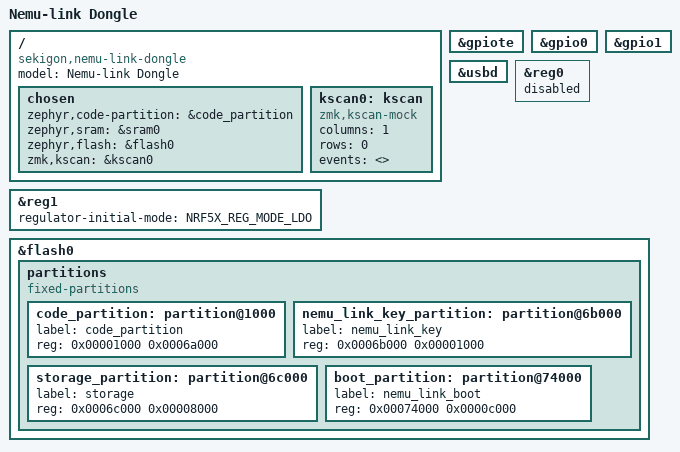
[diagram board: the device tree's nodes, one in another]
/*
 * Copyright (c) 2026 sekigon-gonnoc
 *
 * USB receiver using the nRF52833 clock and UF2 flash layout.
 * This module is intended exclusively for Nemu Link dongles; do not use it
 * with other boards.
 */

/* Devicetree syntax is not C. */
/* clang-format off */
/dts-v1/;

#include <nordic/nrf52833_qiaa.dtsi>
#include <common/nordic/nrf52833_uf2_boot_mode.dtsi>

/ {
    model = "Nemu-link Dongle";
    compatible = "sekigon,nemu-link-dongle";

    chosen {
        zephyr,code-partition = &code_partition;
        zephyr,sram = &sram0;
        zephyr,flash = &flash0;
        zmk,kscan = &kscan0;
    };

    /* Remote ESB input supplies positions; this board has no key matrix. */
    kscan0: kscan {
        compatible = "zmk,kscan-mock";
        columns = <1>;
        rows = <0>;
        events = <>;
    };
};

&gpiote {
    status = "okay";
};

&gpio0 {
    status = "okay";
};

&gpio1 {
    status = "okay";
};

zephyr_udc0: &usbd {
    status = "okay";
};

&reg0 {
    status = "disabled";
};

&reg1 {
    regulator-initial-mode = <NRF5X_REG_MODE_LDO>;
};

&flash0 {
    partitions {
        compatible = "fixed-partitions";
        #address-cells = <1>;
        #size-cells = <1>;

        code_partition: partition@1000 {
            label = "code_partition";
            reg = <0x00001000 0x0006a000>;
        };

        nemu_link_key_partition: partition@6b000 {
            label = "nemu_link_key";
            reg = <0x0006b000 0x00001000>;
        };

        storage_partition: partition@6c000 {
            label = "storage";
            reg = <0x0006c000 0x00008000>;
        };

        boot_partition: partition@74000 {
            label = "nemu_link_boot";
            reg = <0x00074000 0x0000c000>;
        };
    };
};
/* clang-format on */
